# MSPM0G5187 register map
Vendor: Texas Instruments; File version: Revised: 2025-07-22 15:38:34
CPU: CM0 r0p1, little endian, MPU, no FPU, 3 interrupt priority bits
Registers are 32-bit, read-write, reset 0x0 unless marked. A register's access mark holds for its fields unless they carry their own. Offsets are from the block's base; [hi:lo] are bit positions; lines under a group give offsets from that group; {n}, {i} and the like mark numbered series; 'fields as' and 'values as' point back to an identical list; <NAME> marks a mode.

## UC0_UART — PERIPHERALREGION
Base 0x40A00000
0x1000 UC0_UART_CLKDIV — Clock Divider
  [2:0] RATIO — Selects divide ratio of module clock Division factor 0 : DIV_BY_1 1 : DIV_BY_2 .... 63: DIV_BY_64
    0=DIV_BY_1 (Do not divide clock source); {v}=DIV_BY_{v+1} (Divide clock source by {v+1}) (v=1..7); {v}=DIV_BY_{v+1} (Divide clock source by 8) (v=60..63)
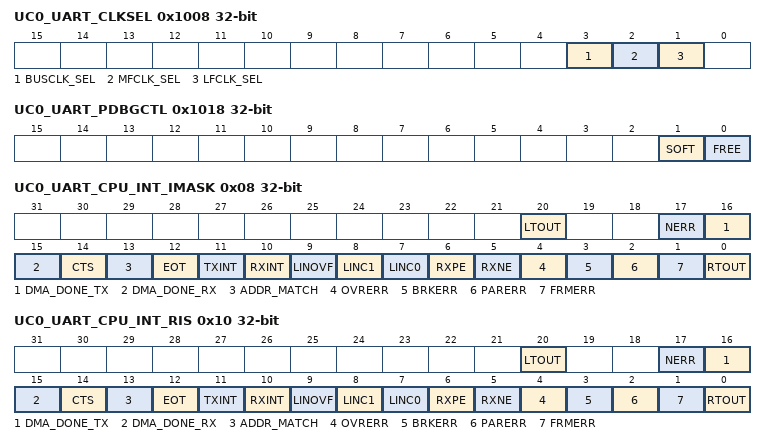
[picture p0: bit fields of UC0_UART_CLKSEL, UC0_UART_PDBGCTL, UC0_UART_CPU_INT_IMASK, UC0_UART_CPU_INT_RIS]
0x1008 UC0_UART_CLKSEL — Clock Select for Ultra Low Power peripherals
  [all] fields
    0=DISABLE (Does not select this clock as a source); 1=ENABLE (Select this clock as a source)
  [3] BUSCLK_SEL — Selects BUS CLK as clock source if enabled
  [2] MFCLK_SEL — Selects MFCLK as clock source if enabled
  [1] LFCLK_SEL — Selects LFCLK as clock source if enabled
0x1018 UC0_UART_PDBGCTL — Peripheral Debug Control
  [1] SOFT — Soft halt boundary control. This function is only available, if [FREE] is set to 'STOP'
    0=DEPRECATED (Not supported); 1=DELAYED (The peripheral blocks the debug freeze until it has reached a boundary where it can resume without corruption)
  [0] FREE — Free run control
    0=STOP (The peripheral freezes functionality while the Core Halted input is asserted and resumes when it is deasserted.); 1=RUN (The peripheral ignores the state of the Core Halted input)
{0x1020+0x2C*i} UC0_UART_CPU_INT[{i}] (i=0..0) group
  0x00 UC0_UART_IIDX ro — Interrupt index
    [7:0] STAT — UART Module Interrupt Vector Value. This register provides the highes priority interrupt index. A read clears the corresponding interrupt flag in RIS and MIS registers. 15h-1Fh = Reserved
      0=NO_INTR (No interrupt pending); 1=RTFG (UART receive time-out interrupt; Interrupt Flag: RT; Interrupt Priority: Highest); 2=FEFG (UART framing error interrupt; Interrupt Flag: FE); 3=PEFG (UART parity error interrupt; Interrupt Flag: PE); 4=BEFG (UART break error interrupt; Interrupt Flag: BE); 5=OEFG (UART receive overrun error interrupt; Interrupt Flag: OE); 6=RXNE (Negative edge on UARTxRXD interrupt; Interrupt Flag: RXNE); 7=RXPE (Positive edge on UARTxRXD interrupt; Interrupt Flag: RXPE); 8=LINC0 (LIN capture 0 / match interrupt; Interrupt Flag: LINC0); 9=LINC1 (LIN capture 1 interrupt; Interrupt Flag: LINC1); 10=LINOVF (LIN hardware counter overflow interrupt; Interrupt Flag: LINOVF); 11=RXIFG (UART receive interrupt; Interrupt Flag: RX); 12=TXIFG (UART transmit interrupt; Interrupt Flag: TX); 13=EOT (UART end of transmission interrupt (transmit serializer empty); Interrupt Flag: EOT); 14=ADDR_MATCH (9-bit mode address match interrupt; Interrupt Flag: ADDR_MATCH); 15=CTS (UART Clear to Send Modem interrupt; Interrupt Flag: CTS); 16=DMA_DONE_RX (DMA DONE on RX); 17=DMA_DONE_TX (DMA DONE on TX); 18=NERR_EVT (Noise Error Event); 19=DMA_PREIRQ_RX (DMA PRE IRQ INTERRUPT); 20=DMA_PREIRQ_TX (DMA PRE IRQ INTERRUPT); 21=LTFG (UART line time-out interrupt; Interrupt Flag)
  0x08 UC0_UART_CPU_INT_IMASK — Interrupt mask
    [20] LTOUT — Enable UARTOUT Line Time-Out Interrupt.
      0=CLR (Clear Interrupt Mask); 1=SET (Set Interrupt Mask)
    [17] NERR — Noise Error on triple voting. Asserted when the 3 samples of majority voting are not equal
      0=CLR (Clear Interrupt Mask); 1=SET (Set Interrupt Mask)
    [16] DMA_DONE_TX — Enable DMA Done on TX Event Channel Interrupt
      0=CLR (Interrupt disabled); 1=SET (Set Interrupt Mask)
    [15] DMA_DONE_RX — Enable DMA Done on RX Event Channel Interrupt
      0=CLR (Interrupt disabled); 1=SET (Set Interrupt Mask)
    [14] CTS — Enable UART Clear to Send Modem Interrupt.
      0=CLR (Interrupt disabled); 1=SET (Set Interrupt Mask)
    [13] ADDR_MATCH — Enable Address Match Interrupt.
      0=CLR (Clear Interrupt Mask); 1=SET (Set Interrupt Mask)
    [12] EOT — Enable UART End of Transmission Interrupt Indicates that the last bit of all transmitted data and flags has left the serializer and without any further Data in the TX Fifo or Buffer.
      0=CLR (Clear Interrupt Mask); 1=SET (Set Interrupt Mask)
    [11] TXINT — Enable UART Transmit Interrupt.
      0=CLR (Clear Interrupt Mask); 1=SET (Set Interrupt Mask)
    [10] RXINT — Enable UART Receive Interrupt.
      0=CLR (Clear Interrupt Mask); 1=SET (Set Interrupt Mask)
    [9] LINOVF — Enable LIN Hardware Counter Overflow Interrupt.
      0=CLR (Clear Interrupt Mask); 1=SET (Set Interrupt Mask)
    [8] LINC1 — Enable LIN Capture 1 Interrupt.
      0=CLR (Clear Interrupt Mask); 1=SET (Set Interrupt Mask)
    [7] LINC0 — Enable LIN Capture 0 / Match Interrupt .
      0=CLR (Clear Interrupt Mask); 1=SET (Set Interrupt Mask)
    [6] RXPE — Enable Positive Edge on UARTxRXD Interrupt.
      0=CLR (Clear Interrupt Mask); 1=SET (Set Interrupt Mask)
    [5] RXNE — Enable Negative Edge on UARTxRXD Interrupt.
      0=CLR (Clear Interrupt Mask); 1=SET (Set Interrupt Mask)
    [4] OVRERR — Enable UART Receive Overrun Error Interrupt.
      0=CLR (Clear Interrupt Mask); 1=SET (Set Interrupt Mask)
    [3] BRKERR — Enable UART Break Error Interrupt.
      0=CLR (Clear Interrupt Mask); 1=SET (Set Interrupt Mask)
    [2] PARERR — Enable UART Parity Error Interrupt.
      0=CLR (Clear Interrupt Mask); 1=SET (Set Interrupt Mask)
    [1] FRMERR — Enable UART Framing Error Interrupt.
      0=CLR (Clear Interrupt Mask); 1=SET (Set Interrupt Mask)
    [0] RTOUT — Enable UARTOUT Receive Time-Out Interrupt.
      0=CLR (Clear Interrupt Mask); 1=SET (Set Interrupt Mask)
  0x10 UC0_UART_CPU_INT_RIS ro — Raw interrupt status
    [20] LTOUT — UARTOUT Line Time-Out Interrupt. Set: no start edge has been detected for an additional character period after reception of last character. This is irrespective of FIFO contents Clear: timeout has not occured
      0=CLR (Interrupt did not occur); 1=SET (Interrupt occurred)
    [17] NERR — Noise Error on triple voting. Asserted when the 3 samples of majority voting are not equal
      0=CLR (Interrupt did not occur); 1=SET (Interrupt occurred)
    [16] DMA_DONE_TX — DMA Done on TX Event Channel Interrupt
      0=CLR (Interrupt disabled); 1=SET (Interrupt occurred)
    [15] DMA_DONE_RX — DMA Done on RX Event Channel Interrupt
      0=CLR (Interrupt disabled); 1=SET (Interrupt occurred)
    [14] CTS — UART Clear to Send Modem Interrupt. This interrupt is raised when CTS toggles, either from '0' to '1' or from '1' to '0'.
      0=CLR (Interrupt disabled); 1=SET (Interrupt occurred)
    [13] ADDR_MATCH — Address Match Interrupt.
      0=CLR (Interrupt did not occur); 1=SET (Interrupt occurred)
    [12] EOT — UART End of Transmission Interrupt Indicates that the last bit of all transmitted data and flags has left the serializer and without any further Data in the TX Fifo or Buffer.
      0=CLR (Interrupt did not occur); 1=SET (Interrupt occurred)
    [11] TXINT — UART Transmit Interrupt.
      0=CLR (Interrupt did not occur); 1=SET (Interrupt occurred)
    [10] RXINT — UART Receive Interrupt.
      0=CLR (Interrupt did not occur); 1=SET (Interrupt occurred)
    [9] LINOVF — LIN Hardware Counter Overflow Interrupt.
      0=CLR (Interrupt did not occur); 1=SET (Interrupt occurred)
    [8] LINC1 — LIN Capture 1 Interrupt.
      0=CLR (Interrupt did not occur); 1=SET (Interrupt occurred)
    [7] LINC0 — LIN Capture 0 / Match Interrupt .
      0=CLR (Interrupt did not occur); 1=SET (Interrupt occurred)
    [6] RXPE — Positive Edge on UARTxRXD Interrupt.
      0=CLR (Interrupt did not occur); 1=SET (Interrupt occurred)
    [5] RXNE — Negative Edge on UARTxRXD Interrupt.
      0=CLR (Interrupt did not occur); 1=SET (Interrupt occurred)
    [4] OVRERR — UART Receive Overrun Error Interrupt. UART Receive Overrun Error Interrupt is raised when the receive FIFO is flow and a new frame is received
      0=CLR (Interrupt did not occur); 1=SET (Interrupt occurred)
    [3] BRKERR — UART Break Error Interrupt. Break Error Interrupt is raised when all data bits, parity bit and stop bits are '0'
      0=CLR (Interrupt did not occur); 1=SET (Interrupt occurred)
    [2] PARERR — UART Parity Error Interrupt.
      0=CLR (Interrupt did not occur); 1=SET (Interrupt occurred)
    [1] FRMERR — UART Framing Error Interrupt. Framing error interrupt is raised when a "low" stop bit is detected.
      0=CLR (Interrupt did not occur); 1=SET (Interrupt occurred)
    [0] RTOUT — UARTOUT Receive Time-Out Interrupt. Interupt is raised when a time-out has lapsed and there are still items in the FIFO
      0=CLR (Interrupt did not occur); 1=SET (Interrupt occurred)
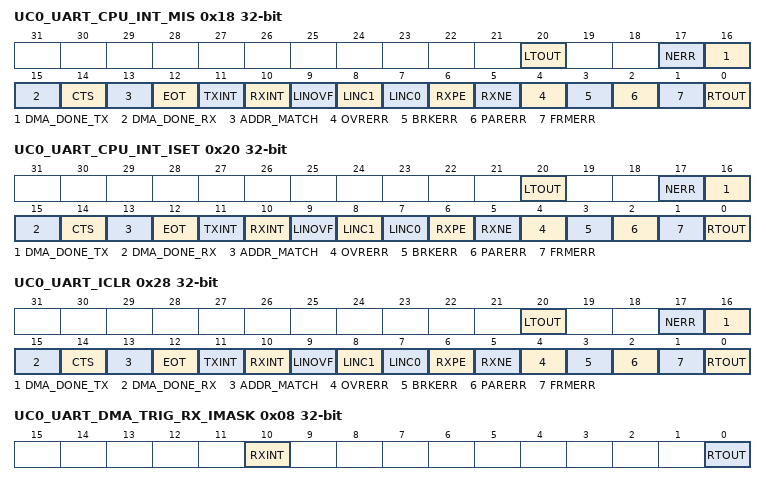
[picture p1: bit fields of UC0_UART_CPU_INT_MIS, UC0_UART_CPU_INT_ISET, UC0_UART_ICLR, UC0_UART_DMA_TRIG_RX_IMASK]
  0x18 UC0_UART_CPU_INT_MIS ro — Masked interrupt status
    [all] fields
      0=CLR (Interrupt did not occur); 1=SET (Interrupt occurred)
    [20] LTOUT — Masked UARTOUT Line Time-Out Interrupt.
    [17] NERR — Noise Error on triple voting. Asserted when the 3 samples of majority voting are not equal
    [16] DMA_DONE_TX — Masked DMA Done on TX Event Channel Interrupt
    [15] DMA_DONE_RX — Masked DMA Done on RX Event Channel Interrupt
    [14] CTS — Masked UART Clear to Send Modem Interrupt.
    [13] ADDR_MATCH — Masked Address Match Interrupt.
    [12] EOT — UART End of Transmission Interrupt Indicates that the last bit of all transmitted data and flags has left the serializer and without any further Data in the TX Fifo or Buffer.
    [11] TXINT — Masked UART Transmit Interrupt.
    [10] RXINT — Masked UART Receive Interrupt.
    [9] LINOVF — Masked LIN Hardware Counter Overflow Interrupt.
    [8] LINC1 — Masked LIN Capture 1 Interrupt.
    [7] LINC0 — Masked LIN Capture 0 / Match Interrupt .
    [6] RXPE — Masked Positive Edge on UARTxRXD Interrupt.
    [5] RXNE — Masked Negative Edge on UARTxRXD Interrupt.
    [4] OVRERR — Masked UART Receive Overrun Error Interrupt.
    [3] BRKERR — Masked UART Break Error Interrupt.
    [2] PARERR — Masked UART Parity Error Interrupt.
    [1] FRMERR — Masked UART Framing Error Interrupt.
    [0] RTOUT — Masked UARTOUT Receive Time-Out Interrupt.
  0x20 UC0_UART_CPU_INT_ISET wo — Interrupt set
    [20] LTOUT — Set UARTOUT Line Time-Out Interrupt.
      0=NO_EFFECT (Writing 0 has no effect); 1=SET (Set Interrupt)
    [17] NERR — Noise Error on triple voting. Asserted when the 3 samples of majority voting are not equal
      0=NO_EFFECT (Writing this has no effect); 1=SET (Set the interrupt)
    [16] DMA_DONE_TX — Set DMA Done on TX Event Channel Interrupt
      0=NO_EFFECT (Interrupt disabled); 1=SET (Set Interrupt)
    [15] DMA_DONE_RX — Set DMA Done on RX Event Channel Interrupt
      0=NO_EFFECT (Interrupt disabled); 1=SET (Set Interrupt)
    [14] CTS — Set UART Clear to Send Modem Interrupt.
      0=NO_EFFECT (Writing 0 has no effect); 1=SET (Set Interrupt)
    [13] ADDR_MATCH — Set Address Match Interrupt.
      0=NO_EFFECT (Writing 0 has no effect); 1=SET (Set Interrupt)
    [12] EOT — Set UART End of Transmission Interrupt Indicates that the last bit of all transmitted data and flags has left the serializer and without any further Data in the TX Fifo or Buffer.
      0=NO_EFFECT (Writing 0 has no effect); 1=SET (Set Interrupt)
    [11] TXINT — Set UART Transmit Interrupt.
      0=NO_EFFECT (Writing 0 has no effect); 1=SET (Set Interrupt)
    [10] RXINT — Set UART Receive Interrupt.
      0=NO_EFFECT (Writing 0 has no effect); 1=SET (Set Interrupt)
    [9] LINOVF — Set LIN Hardware Counter Overflow Interrupt.
      0=NO_EFFECT (Writing 0 has no effect); 1=SET (Set Interrupt)
    [8] LINC1 — Set LIN Capture 1 Interrupt.
      0=NO_EFFECT (Writing 0 has no effect); 1=SET (Set Interrupt)
    [7] LINC0 — Set LIN Capture 0 / Match Interrupt .
      0=NO_EFFECT (Writing 0 has no effect); 1=SET (Set Interrupt)
    [6] RXPE — Set Positive Edge on UARTxRXD Interrupt.
      0=NO_EFFECT (Writing 0 has no effect); 1=SET (Set Interrupt)
    [5] RXNE — Set Negative Edge on UARTxRXD Interrupt.
      0=NO_EFFECT (Writing 0 has no effect); 1=SET (Set Interrupt)
    [4] OVRERR — Set UART Receive Overrun Error Interrupt.
      0=NO_EFFECT (Writing 0 has no effect); 1=SET (Set Interrupt)
    [3] BRKERR — Set UART Break Error Interrupt.
      0=NO_EFFECT (Writing 0 has no effect); 1=SET (Set Interrupt)
    [2] PARERR — Set UART Parity Error Interrupt.
      0=NO_EFFECT (Writing 0 has no effect); 1=SET (Set Interrupt)
    [1] FRMERR — Set UART Framing Error Interrupt.
      0=NO_EFFECT (Writing 0 has no effect); 1=SET (Set Interrupt)
    [0] RTOUT — Set UARTOUT Receive Time-Out Interrupt.
      0=NO_EFFECT (Writing 0 has no effect); 1=SET (Set Interrupt)
  0x28 UC0_UART_ICLR wo — Interrupt clear
    [20] LTOUT — Clear UARTOUT Line Time-Out Interrupt.
      0=NO_EFFECT (Writing 0 has no effect); 1=CLR (Clear Interrupt)
    [17] NERR — Noise Error on triple voting. Asserted when the 3 samples of majority voting are not equal
      values as LTOUT
    [16] DMA_DONE_TX — Clear DMA Done on TX Event Channel Interrupt
      0=NO_EFFECT (Interrupt disabled); 1=CLR (Clear Interrupt)
    [15] DMA_DONE_RX — Clear DMA Done on RX Event Channel Interrupt
      0=NO_EFFECT (Interrupt disabled); 1=CLR (Clear Interrupt)
    [14] CTS — Clear UART Clear to Send Modem Interrupt.
      values as LTOUT
    [13] ADDR_MATCH — Clear Address Match Interrupt.
      values as LTOUT
    [12] EOT — Clear UART End of Transmission Interrupt Indicates that the last bit of all transmitted data and flags has left the serializer and without any further Data in the TX Fifo or Buffer.
      values as LTOUT
    [11] TXINT — Clear UART Transmit Interrupt.
      values as LTOUT
    [10] RXINT — Clear UART Receive Interrupt.
      values as LTOUT
    [9] LINOVF — Clear LIN Hardware Counter Overflow Interrupt.
      values as LTOUT
    [8] LINC1 — Clear LIN Capture 1 Interrupt.
      values as LTOUT
    [7] LINC0 — Clear LIN Capture 0 / Match Interrupt .
      values as LTOUT
    [6] RXPE — Clear Positive Edge on UARTxRXD Interrupt.
      values as LTOUT
    [5] RXNE — Clear Negative Edge on UARTxRXD Interrupt.
      values as LTOUT
    [4] OVRERR — Clear UART Receive Overrun Error Interrupt.
      values as LTOUT
    [3] BRKERR — Clear UART Break Error Interrupt.
      values as LTOUT
    [2] PARERR — Clear UART Parity Error Interrupt.
      values as LTOUT
    [1] FRMERR — Clear UART Framing Error Interrupt.
      values as LTOUT
    [0] RTOUT — Clear UARTOUT Receive Time-Out Interrupt.
      values as LTOUT
{0x1050+0x24*i} UC0_UART_DMA_TRIG_RX[{i}] (i=0..0) group
  0x08 UC0_UART_DMA_TRIG_RX_IMASK — Interrupt mask
    [10] RXINT — Enable UART Receive Interrupt.
      0=CLR (Clear Interrupt Mask); 1=SET (Set Interrupt Mask)
    [0] RTOUT — Enable UARTOUT Receive Time-Out Interrupt.
      0=CLR (Clear Interrupt Mask); 1=SET (Set Interrupt Mask)
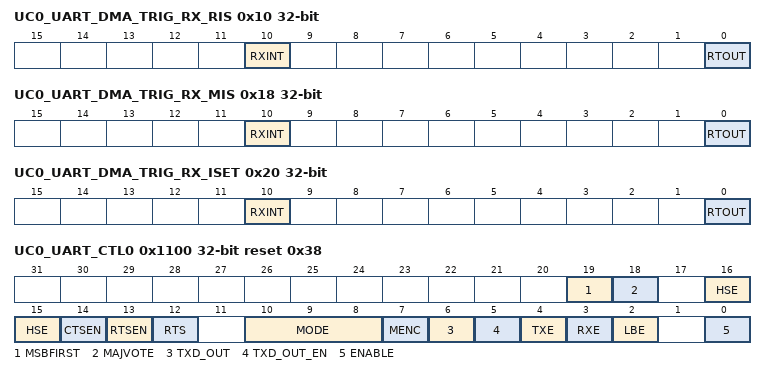
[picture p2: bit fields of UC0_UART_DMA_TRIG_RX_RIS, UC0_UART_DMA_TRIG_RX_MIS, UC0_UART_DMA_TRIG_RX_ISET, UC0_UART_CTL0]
  0x10 UC0_UART_DMA_TRIG_RX_RIS ro — Raw interrupt status
    [10] RXINT — UART Receive Interrupt.
      0=CLR (Interrupt did not occur); 1=SET (Interrupt occurred)
    [0] RTOUT — UARTOUT Receive Time-Out Interrupt.
      0=CLR (Interrupt did not occur); 1=SET (Interrupt occurred)
  0x18 UC0_UART_DMA_TRIG_RX_MIS ro — Masked interrupt status
    [10] RXINT — Masked UART Receive Interrupt.
      0=CLR (Interrupt did not occur); 1=SET (Interrupt occurred)
    [0] RTOUT — Masked UARTOUT Receive Time-Out Interrupt.
      0=CLR (Interrupt did not occur); 1=SET (Interrupt occurred)
  0x20 UC0_UART_DMA_TRIG_RX_ISET wo — Interrupt set
    [10] RXINT — Set UART Receive Interrupt.
      0=NO_EFFECT (Writing 0 has no effect); 1=SET (Set Interrupt)
    [0] RTOUT — Set UARTOUT Receive Time-Out Interrupt.
      0=NO_EFFECT (Writing 0 has no effect); 1=SET (Set Interrupt)
{0x1080+0x24*i} UC0_UART_DMA_TRIG_TX[{i}] (i=0..0) group
  0x08 UC0_UART_DMA_TRIG_TX_IMASK — Interrupt mask
    [11] TXINT — Enable UART Transmit Interrupt.
      0=CLR (Clear Interrupt Mask); 1=SET (Set Interrupt Mask)
  0x10 UC0_UART_DMA_TRIG_TX_RIS ro — Raw interrupt status
    [11] TXINT — UART Transmit Interrupt.
      0=CLR (Interrupt did not occur); 1=SET (Interrupt occurred)
  0x18 UC0_UART_DMA_TRIG_TX_MIS ro — Masked interrupt status
    [11] TXINT — Masked UART Transmit Interrupt.
      0=CLR (Interrupt did not occur); 1=SET (Interrupt occurred)
  0x20 UC0_UART_DMA_TRIG_TX_ISET wo — Interrupt set
    [11] TXINT — Set UART Transmit Interrupt.
      0=NO_EFFECT (Writing 0 has no effect); 1=SET (Set Interrupt)
0x10E4 UC0_UART_INTCTL wo — Interrupt control register
  [0] INTEVAL — Writing a 1 to this field re-evaluates the interrupt sources.
    0=DISABLE (The interrupt or event line is disabled.); 1=EVAL (The interrupt or event line is in software mode. Software must clear the RIS.)
0x1100 UC0_UART_CTL0 reset 0x38 — UART Control Register 0
  [19] MSBFIRST — Most Significant Bit First This bit has effect both on the way protocol byte is transmitted and received. Notes: User needs to match the protocol to the correct value of this bit to send MSb or LSb first. The hardware engine will send the byte entirely based on this bit.
    0=DISABLE (Least significant bit is sent first in the protocol packet); 1=ENABLE (Most significant bit is sent first in the protocol packet)
  [18] MAJVOTE — Majority Vote Enable When Majority Voting is enabled, the three center bits are used to determine received sample value. In case of error (i.e. all 3 bits are not the same), noise error is detected and bits RIS.NERR and register RXDATA.NERR are set. Oversampling of 16 : bits 7, 8, 9 are used Oversampling of 8 : bits 3, 4, 5 are used Disabled : Single sample value (center value) used
    0=DISABLE (Majority voting is disabled); 1=ENABLE (Majority voting is enabled)
  [16:15] HSE — High-Speed Bit Oversampling Enable #b#NOTE:#/b# The bit oversampling influences the UART baud-rate configuration. The state of this bit has no effect on clock generation in ISO7816 smart card mode (the SMART bit is set).
    0=OVS16 (16x oversampling.); 1=OVS8 (8x oversampling.); 2=OVS3 (3x oversampling. IrDA, Manchester and DALI not supported when 3x oversampling is enabled.)
  [14] CTSEN — Enable Clear To Send
    0=DISABLE (CTS hardware flow control is disabled.); 1=ENABLE (CTS hardware flow control is enabled. Data is only transmitted when the UARTxCTS signal is asserted.)
  [13] RTSEN — Enable hardware controlled Request to Send
    0=DISABLE (RTS hardware flow control is disabled.); 1=ENABLE (RTS hardware flow control is enabled. Data is only requested (by asserting UARTxRTS) when the receive FIFO/buffer has available entries.)
  [12] RTS — Request to Send If RTSEN is set the RTS output signals is controlled by the hardware logic using the FIFO fill level or buffer status. If RTSEN is cleared the RTS output is controlled by the RTS bit. The bit is the complement of the UART request to send, RTS modem status output.
    0=CLR (Signal not RTS); 1=SET (Signal RTS)
  [10:8] MODE — Set the communication mode and protocol used. (Not defined settings uses the default setting: 0)
    0=UART (Normal operation); 1=RS485 (RS485 mode: UART needs to be IDLE with receiving data for the in EXTDIR_HOLD set time. EXTDIR_SETUP defines the time the RTS line is set to high before sending. When the buffer is empty the RTS line is set low again. A transmit will be delayed as long the UART is receiving data.); 2=IDLELINE (The UART operates in IDLE Line Mode); 3=ADDR9BIT (The UART operates in 9 Bit Address mode); 4=SMART (ISO7816 Smart Card Support The application must ensure that it sets 8-bit word length (WLEN set to 3h) and even parity (PEN set to 1, EPS set to 1, SPS set to 0) in UARTLCRH when using ISO7816 mode. The value of the STP2 bit in UARTLCRH is ignored and the number of stop bits is forced to 2.); 5=DALI (DALI Mode:)
  [7] MENC — Manchester Encode enable
    0=DISABLE (Disable Manchester Encoding); 1=ENABLE (Enable Manchester Encoding)
  [6] TXD_OUT — TXD Pin Control Controls the TXD pin when TXD_OUT_EN = 1 and TXE = 0.
    0=LOW (TXD pin is low); 1=HIGH (TXD pin is high)
  [5] TXD_OUT_EN — TXD Pin Control Enable. When the transmit section of the UART is disabled (TXE = 0), the TXD pin can be controlled by the TXD_OUT bit.
    0=DISABLE (TXD pin can not be controlled by TXD_OUT); 1=ENABLE (TXD pin can be controlled by TXD_OUT)
  [4] TXE — UART Transmit Enable If the UART is disabled in the middle of a transmission, it completes the current character before stopping. #b#NOTE:#/b# To enable transmission, the UARTEN bit must be set.
    0=DISABLE (The transmit section of the UART is disabled. The UARTxTXD pin of the UART can be controlled by the TXD_CTL bit when enabled.); 1=ENABLE (The transmit section of the UART is enabled.)
  [3] RXE — UART Receive Enable If the UART is disabled in the middle of a receive, it completes the current character before stopping. #b#NOTE:#/b# To enable reception, the UARTEN bit must be set.
    0=DISABLE (The receive section of the UART is disabled.); 1=ENABLE (The receive section of the UART is enabled.)
  [2] LBE — UART Loop Back Enable
    0=DISABLE (Normal operation.); 1=ENABLE (The UARTxTX path is fed through the UARTxRX path internally.)
  [0] ENABLE — UART Module Enable. If the UART is disabled in the middle of transmission or reception, it completes the current character before stopping. If the ENABLE bit is not set, all registers can still be accessed and updated. It is recommended to setup and change the UART operation mode with having the ENABLE bit cleared to avoid unpredictable behavior during the setup or update. If disabled the UART module will not send or receive any data and the logic is held in reset state.
    0=DISABLE (Disable Module); 1=ENABLE (Enable module)
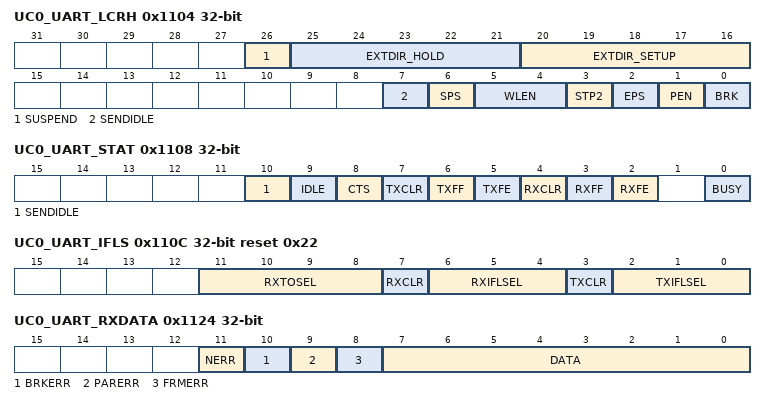
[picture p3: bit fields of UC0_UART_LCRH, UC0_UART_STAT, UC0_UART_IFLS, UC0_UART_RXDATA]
0x1104 UC0_UART_LCRH — UART Line Control Register
  [26] SUSPEND — Suspend external communication
    0=DISABLE (Functional mode resumed); 1=ENABLE (External communication suspended)
  [25:21] EXTDIR_HOLD — Defines the number of UARTclk ticks the signal to control the external driver for the RS485 will be reset after the beginning of the stop bit. (If 2 STOP bits are enabled the beginning of the 2nd STOP bit.)
  [20:16] EXTDIR_SETUP — Defines the number of UARTclk ticks the signal to control the external driver for the RS485 will be set before the START bit is send
  [7] SENDIDLE — UART send IDLE pattern. When this bit is set, SENDIDLE period of 11 bit times will be sent on the TX line. Read STAT.SENDIDLE bit to readback current status of SENDIDLE
    0=DISABLE (Normal operation); 1=ENABLE (Send Idle Pattern)
  [6] SPS — UART Stick Parity Select The Stick Parity Select (SPS) bit is used to set either a permanent '1' or a permanent '0' as parity when transmitting or receiving data. Its purpose is to typically indicate the first byte of a package or to mark an address byte, for example in a multi-drop RS-485 network. When bits PEN, EPS, and SPS of UARTLCRH are set, the parity bit is transmitted and checked as a 0. When bits PEN and SPS are set and EPS is cleared, the parity bit is transmitted and checked as a 1.
    0=DISABLE (Disable Stick Parity); 1=ENABLE (Enable Stick Parity)
  [5:4] WLEN — UART Word Length The bits indicate the number of data bits transmitted or received in a frame as follows:
    0=DATABIT5 (5 bits (default)); 1=DATABIT6 (6 bits); 2=DATABIT7 (7 bits); 3=DATABIT8 (8 bits)
  [3] STP2 — UART Two Stop Bits Select When in 7816 smart card mode (the SMART bit is set in the UARTCTL register), the number of stop bits is forced to 2.
    0=DISABLE (One stop bit is transmitted at the end of a frame.); 1=ENABLE (Two stop bits are transmitted at the end of a frame. The receive logic checks for two stop bits being received and provide Frame Error if either is invalid.)
  [2] EPS — UART Even Parity Select This bit has no effect when parity is disabled by the PEN bit. For 9-Bit UART Mode transmissions, this bit controls the address byte and data byte indication (9th bit). 0 = The transferred byte is a data byte 1 = The transferred byte is an address byte
    0=ODD (Odd parity is performed, which checks for an odd number of 1s.); 1=EVEN (Even parity generation and checking is performed during transmission and reception, which checks for an even number of 1s in data and parity bits.)
  [1] PEN — UART Parity Enable
    0=DISABLE (Parity is disabled and no parity bit is added to the data frame.); 1=ENABLE (Parity checking and generation is enabled.)
  [0] BRK — UART Send Break (for LIN Protocol) 1. Break condition is sent on the line for as long as this bit is set
    0=DISABLE (Normal operation); 1=ENABLE (A low level is continually output on the UARTxTXD signal, after completing transmission of the current character. For the proper execution of the break command, software must set this bit for at least two frames (character periods).)
0x1108 UC0_UART_STAT ro — UART Status Register
  [10] SENDIDLE — TX FIFO Clear Status
    0=CLEARED (IDLE condition has not yet been sent on the line); 1=SET (IDLE condition has been sent on the line)
  [9] IDLE — IDLE mode has been detected in Idleline-Multiprocessor-Mode. The IDLE bit is used as an address tag for each block of characters. In idle-line multiprocessor format, this bit is set when a received character is an address.
    0=CLEARED (IDLE has not been detected before last received character. (In idle-line multiprocessor mode).); 1=SET (IDLE has been detected before last received character. (In idle-line multiprocessor mode).)
  [8] CTS — Clear To Send
    0=CLEARED (The CTS signal is not asserted (high).); 1=SET (The CTS signal is asserted (low).)
  [7] TXCLR — TX FIFO Clear Status
    0=CLEARED (FIFO is not cleared); 1=SET (FIFO clear is complete)
  [6] TXFF — UART Transmit FIFO Full The meaning of this bit depends on the state of the FEN bit in the CTL0 register.
    0=CLEARED (The transmitter is not full.); 1=SET (transmit FIFO is full.)
  [5] TXFE — UART Transmit FIFO Empty
    0=CLEARED (The transmitter has data to transmit.); 1=SET (transmit FIFO is empty.)
  [4] RXCLR — RX FIFO Clear Status
    values as TXCLR
  [3] RXFF — UART Receive FIFO Full
    0=CLEARED (The receiver can receive data.); 1=SET (receive FIFO is full.)
  [2] RXFE — UART Receive FIFO Empty
    0=CLEARED (The receiver is not empty.); 1=SET (eceive FIFO is empty.)
  [0] BUSY — UART Busy This bit is set as soon as the transmit FIFO/buffer becomes non-empty (regardless of whether UART is enabled) or if a receive data is currently ongoing (after the start edge have been detected until a complete byte, including all stop bits, has been received by the shift register). In IDLE_Line mode the Busy signal also stays set during the idle time generation.
    0=CLEARED (The UART is not busy.); 1=SET (The UART is busy transmitting data. This bit remains set until the complete byte, including all stop bits, has been sent/received from/into the shift register.)
0x110C UC0_UART_IFLS reset 0x22 — UART Interrupt FIFO Level Select Register
  [11:8] RXTOSEL — UART Receive Interrupt Timeout Select. When receiving no start edge for an additional character within the set bittimes a RX interrupt is set even if the FIFO level is not reached. A value of 0 disables this function.
  [7] RXCLR — RX FIFO CLEAR. Setting this bit will clear the RX FIFO contents.
    0=DISABLE (Disable FIFO clear); 1=ENABLE (Enable FIFO Clear)
  [6:4] RXIFLSEL — FIFO Level Select for generating events (interrupt/dma). Note: for undefined settings the default configuration is used.
    1=LVL_1_4 (RX FIFO >= 1/4 full); 2=LVL_1_2 (RX FIFO >= 1/2 full (default)); 3=LVL_3_4 (RX FIFO >= 3/4 full); 4=LVL_NOT_EMPTY (Opposite of empty); 5=LVL_FULL (RX FIFO is full); 6=LVL_ALMOST_FULL (RX_FIFO >= (MAX_FIFO_LEN -1)); 7=LVL_ALMOST_EMPTY (RX_FIFO <= 1)
  [3] TXCLR — TX FIFO CLEAR. Setting this bit will clear the TX FIFO contents.
    0=DISABLE (Disable FIFO clear); 1=ENABLE (Enable FIFO Clear)
  [2:0] TXIFLSEL — FIFO Level Select for generating events (interrupt/dma). Note: for undefined settings the default configuration is used.
    1=LVL_3_4 (TX FIFO <= 3/4 empty); 2=LVL_1_2 (TX FIFO <= 1/2 empty (default)); 3=LVL_1_4 (TX FIFO <= 1/4 empty); 4=LVL_NOT_FULL (Opposite of full); 5=LVL_EMPTY (TX FIFO is empty); 6=LVL_ALMOST_EMPTY (TX FIFO <= 1); 7=LVL_ALMOST_FULL (TX_FIFO >= (MAX_FIFO_LEN -1))
0x1110 UC0_UART_IBRD — UART Integer Baud-Rate Divisor Register
  [15:0] DIVINT — Integer Baud-Rate Divisor
0x1114 UC0_UART_FBRD — UART Fractional Baud-Rate Divisor Register
  [5:0] DIVFRAC — Fractional Baud-Rate Divisor
0x1120 UC0_UART_TXDATA wo — UART Transmit Data Register
  [7:0] DATA — Data Transmitted or Received Data that is to be transmitted via the UART is written to this field. When read, this field contains the data that was received by the UART.
0x1124 UC0_UART_RXDATA ro — UART Receive Data Register
  [11] NERR — Noise Error. Writing to this bit has no effect. The flag is cleared by writing 1 to the NERR bit in the UART EVENT ICLR register.
    0=CLR (No noise error occurred); 1=SET (Noise error occurred during majority voting)
  [10] BRKERR — UART Break Error Writing to this bit has no effect. The flag is cleared by writing 1 to the BRKERR bit in the UART EVENT ICLR register. This error is associated with the character at the top of the FIFO. When a break occurs, only one 0 character is loaded into the FIFO. The next character is only enabled after the receive data input goes to a 1 (marking state) and the next valid start bit is received.
    0=CLR (No break condition has occurred); 1=SET (A break condition has been detected, indicating that the receive data input was held low for longer than a full-word transmission time (defined as start, data, parity, and stop bits).)
  [9] PARERR — UART Parity Error Writing to this bit has no effect. The flag is cleared by writing 1 to the PARERR bit in the UART EVENT ICLR register.
    0=CLR (No parity error has occurred); 1=SET (The parity of the received data character does not match the parity defined by bits 2 and 7 of the UARTLCRH register.)
  [8] FRMERR — UART Framing Error Writing to this bit has no effect. The flag is cleared by writing 1 to the FRMERR bit in the UART EVENT ICLR register. This error is associated with the character at the top of the FIFO.
    0=CLR (No framing error has occurred); 1=SET (The received character does not have a valid stop bit sequence, which is one or two stop bits depending on the UARTLCRH.STP2 setting (a valid stop bit is 1).)
  [7:0] DATA — Received Data. When read, this field contains the data that was received by the UART.
0x1130 UC0_UART_LINCNT — UART LIN Mode Counter Register
  [15:0] VALUE — 16 bit up counter clocked by the functional clock of the UART.
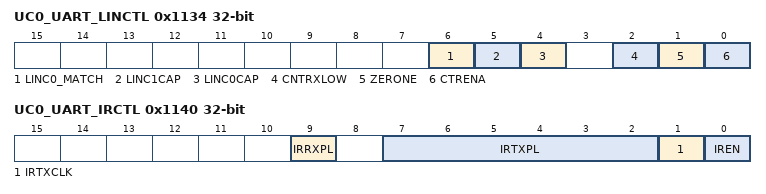
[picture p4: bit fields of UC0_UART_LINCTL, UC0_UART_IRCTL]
0x1134 UC0_UART_LINCTL — UART LIN Mode Control Register
  [6] LINC0_MATCH — Counter Compare Match Mode When this bit is set to 1 a counter compare match with LINC0 register triggers an LINC0 interrupt when enabled.
    0=DISABLE (Counter compare match mode disabled (capture mode enabled)); 1=ENABLE (Counter compare match enabled (capture mode disabled))
  [5] LINC1CAP — Capture Counter on positive RXD Edge. When enabled the counter value is captured to LINC1 register on each positive RXD edge. A LINC1 interrupt is triggered when enabled.
    0=DISABLE (Capture counter on positive UARTxRXD edge disabled); 1=ENABLE (Capture counter on positive UARTxRXD edge enabled)
  [4] LINC0CAP — Capture Counter on negative RXD Edge. When enabled the counter value is captured to LINC0 register on each negative RXD edge. A LINC0 interrupt is triggered when enabled.
    0=DISABLE (Capture counter on negative UARTxRXD edge disabled); 1=ENABLE (Capture counter on negative UARTxRXD edge enabled)
  [2] CNTRXLOW — Count while low Signal on RXD When counter is enabled and the signal on RXD is low, the counter increments.
    0=DISABLE (Count while low Signal on UARTxRXD disabled); 1=ENABLE (Count while low Signal on UARTxRXD enabled)
  [1] ZERONE — Zero on negative Edge of RXD. When enabled the counter is set to 0 and starts counting on a negative edge of RXD
    0=DISABLE (Zero on negative edge disabled); 1=ENABLE (Zero on negative edge enabled)
  [0] CTRENA — LIN Counter Enable. LIN counter will only count when enabled.
    0=DISABLE (Counter disabled); 1=ENABLE (Counter enabled)
0x1138 UC0_UART_LINC0 — UART LIN Mode Capture 0 Register
  [15:0] DATA — 16 Bit Capture / Compare Register Captures current LINCTR value on RXD falling edge and can generate a LINC0 interrupt when capture is enabled (LINC0CAP = 1). If compare mode is enabled (LINC0_MATCH = 1), a counter match can generate a LINC0 interrupt.
0x113C UC0_UART_LINC1 — UART LIN Mode Capture 1 Register
  [15:0] DATA — 16 Bit Capture / Compare Register Captures current LINCTR value on RXD rising edge and can generate a LINC1 interrupt when capture is enabled (LINC1CAP = 1)
0x1140 UC0_UART_IRCTL — eUSCI_Ax IrDA Control Word Register
  [9] IRRXPL — IrDA receive input UCAxRXD polarity
    0=HIGH (IrDA transceiver delivers a high pulse when a light pulse is seen); 1=LOW (IrDA transceiver delivers a low pulse when a light pulse is seen)
  [7:2] IRTXPL — Transmit pulse length. Pulse length t(PULSE) = (IRTXPLx + 1) / [2 * f(IRTXCLK)] (IRTXCLK = functional clock of the UART)
  [1] IRTXCLK — IrDA transmit pulse clock select
    0=BITCLK (IrDA encode data is based on the functional clock.); 1=BRCLK (IrDA encode data is based on the Baud Rate clock< when select 8x oversampling, the IRTXPL cycle should less 8; when select 16x oversampling, the IRTXPL cycle should less 16.)
  [0] IREN — IrDA encoder/decoder enable
    0=DISABLE (IrDA encoder/decoder disabled); 1=ENABLE (IrDA encoder/decoder enabled)
0x1148 UC0_UART_AMASK — Self Address Mask Register
  [7:0] MSK — Self Address Mask for 9-Bit Mode This field contains the address mask that creates a set of addresses that should be matched. A 0 bit in the MSK bitfield configures, that the corresponding bit in the ADDR bitfield of the UARTxADDR register is don't care. A 1 bit in the MSK bitfield configures, that the corresponding bit in the ADDR bitfield of the UARTxADDR register must match.
0x114C UC0_UART_ADDR — Self Address Register
  [7:0] ADDR — Self Address for 9-Bit Mode This field contains the address that should be matched when UARTxAMASK is FFh.

## UC1_UART — PERIPHERALREGION
Base 0x40A02000
Registers as UC0_UART (with UC0_UART read as UC1_UART), without UC0_UART_IRCTL; these are added or differ:
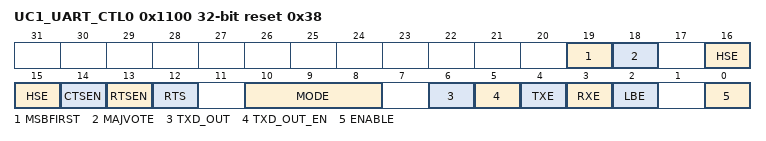
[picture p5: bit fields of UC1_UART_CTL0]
0x1100 UC1_UART_CTL0 reset 0x38 — UART Control Register 0
  [19] MSBFIRST — Most Significant Bit First This bit has effect both on the way protocol byte is transmitted and received. Notes: User needs to match the protocol to the correct value of this bit to send MSb or LSb first. The hardware engine will send the byte entirely based on this bit.
    0=DISABLE (Least significant bit is sent first in the protocol packet); 1=ENABLE (Most significant bit is sent first in the protocol packet)
  [18] MAJVOTE — Majority Vote Enable When Majority Voting is enabled, the three center bits are used to determine received sample value. In case of error (i.e. all 3 bits are not the same), noise error is detected and bits RIS.NERR and register RXDATA.NERR are set. Oversampling of 16 : bits 7, 8, 9 are used Oversampling of 8 : bits 3, 4, 5 are used Disabled : Single sample value (center value) used
    0=DISABLE (Majority voting is disabled); 1=ENABLE (Majority voting is enabled)
  [16:15] HSE — High-Speed Bit Oversampling Enable #b#NOTE:#/b# The bit oversampling influences the UART baud-rate configuration. The state of this bit has no effect on clock generation in ISO7816 smart card mode (the SMART bit is set).
    0=OVS16 (16x oversampling.); 1=OVS8 (8x oversampling.); 2=OVS3 (3x oversampling. IrDA, Manchester and DALI not supported when 3x oversampling is enabled.)
  [14] CTSEN — Enable Clear To Send
    0=DISABLE (CTS hardware flow control is disabled.); 1=ENABLE (CTS hardware flow control is enabled. Data is only transmitted when the UARTxCTS signal is asserted.)
  [13] RTSEN — Enable hardware controlled Request to Send
    0=DISABLE (RTS hardware flow control is disabled.); 1=ENABLE (RTS hardware flow control is enabled. Data is only requested (by asserting UARTxRTS) when the receive FIFO/buffer has available entries.)
  [12] RTS — Request to Send If RTSEN is set the RTS output signals is controlled by the hardware logic using the FIFO fill level or buffer status. If RTSEN is cleared the RTS output is controlled by the RTS bit. The bit is the complement of the UART request to send, RTS modem status output.
    0=CLR (Signal not RTS); 1=SET (Signal RTS)
  [10:8] MODE — Set the communication mode and protocol used. (Not defined settings uses the default setting: 0)
    values as UC0_UART.UC0_UART_CTL0.MODE
  [6] TXD_OUT — TXD Pin Control Controls the TXD pin when TXD_OUT_EN = 1 and TXE = 0.
    0=LOW (TXD pin is low); 1=HIGH (TXD pin is high)
  [5] TXD_OUT_EN — TXD Pin Control Enable. When the transmit section of the UART is disabled (TXE = 0), the TXD pin can be controlled by the TXD_OUT bit.
    0=DISABLE (TXD pin can not be controlled by TXD_OUT); 1=ENABLE (TXD pin can be controlled by TXD_OUT)
  [4] TXE — UART Transmit Enable If the UART is disabled in the middle of a transmission, it completes the current character before stopping. #b#NOTE:#/b# To enable transmission, the UARTEN bit must be set.
    0=DISABLE (The transmit section of the UART is disabled. The UARTxTXD pin of the UART can be controlled by the TXD_CTL bit when enabled.); 1=ENABLE (The transmit section of the UART is enabled.)
  [3] RXE — UART Receive Enable If the UART is disabled in the middle of a receive, it completes the current character before stopping. #b#NOTE:#/b# To enable reception, the UARTEN bit must be set.
    0=DISABLE (The receive section of the UART is disabled.); 1=ENABLE (The receive section of the UART is enabled.)
  [2] LBE — UART Loop Back Enable
    0=DISABLE (Normal operation.); 1=ENABLE (The UARTxTX path is fed through the UARTxRX path internally.)
  [0] ENABLE — UART Module Enable. If the UART is disabled in the middle of transmission or reception, it completes the current character before stopping. If the ENABLE bit is not set, all registers can still be accessed and updated. It is recommended to setup and change the UART operation mode with having the ENABLE bit cleared to avoid unpredictable behavior during the setup or update. If disabled the UART module will not send or receive any data and the logic is held in reset state.
    0=DISABLE (Disable Module); 1=ENABLE (Enable module)
